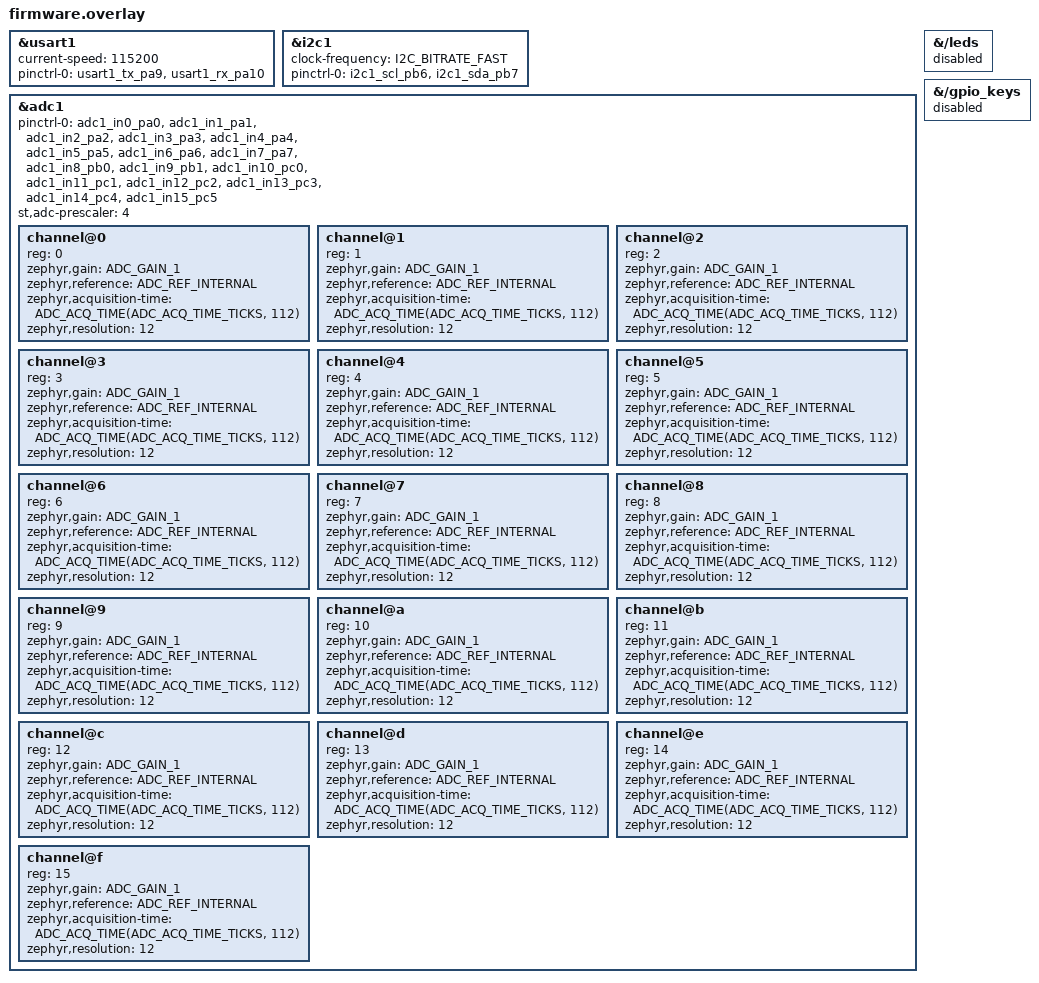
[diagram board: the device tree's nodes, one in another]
&usart1 {
    current-speed = <115200>;
    pinctrl-0 = <&usart1_tx_pa9 &usart1_rx_pa10>;
    pinctrl-names = "default";
    status = "okay";
};

&i2c1 {
    clock-frequency = <I2C_BITRATE_FAST>;
    pinctrl-0 = <&i2c1_scl_pb6 &i2c1_sda_pb7>;
    pinctrl-names = "default";
    status = "okay";
};

&adc1 {
    pinctrl-0 = <&adc1_in0_pa0
                 &adc1_in1_pa1
                 &adc1_in2_pa2
                 &adc1_in3_pa3
                 &adc1_in4_pa4
                 &adc1_in5_pa5
                 &adc1_in6_pa6
                 &adc1_in7_pa7
                 &adc1_in8_pb0
                 &adc1_in9_pb1
                 &adc1_in10_pc0
                 &adc1_in11_pc1
                 &adc1_in12_pc2
                 &adc1_in13_pc3
                 &adc1_in14_pc4
                 &adc1_in15_pc5>;
    pinctrl-names = "default";
    st,adc-prescaler = <4>;
    status = "okay";

    #address-cells = <1>;
    #size-cells = <0>;

    channel@0 {
        reg = <0>;
        zephyr,gain = "ADC_GAIN_1";
        zephyr,reference = "ADC_REF_INTERNAL";
        zephyr,acquisition-time = <ADC_ACQ_TIME(ADC_ACQ_TIME_TICKS, 112)>;
        zephyr,resolution = <12>;
    };

    channel@1 {
        reg = <1>;
        zephyr,gain = "ADC_GAIN_1";
        zephyr,reference = "ADC_REF_INTERNAL";
        zephyr,acquisition-time = <ADC_ACQ_TIME(ADC_ACQ_TIME_TICKS, 112)>;
        zephyr,resolution = <12>;
    };

    channel@2 {
        reg = <2>;
        zephyr,gain = "ADC_GAIN_1";
        zephyr,reference = "ADC_REF_INTERNAL";
        zephyr,acquisition-time = <ADC_ACQ_TIME(ADC_ACQ_TIME_TICKS, 112)>;
        zephyr,resolution = <12>;
    };

    channel@3 {
        reg = <3>;
        zephyr,gain = "ADC_GAIN_1";
        zephyr,reference = "ADC_REF_INTERNAL";
        zephyr,acquisition-time = <ADC_ACQ_TIME(ADC_ACQ_TIME_TICKS, 112)>;
        zephyr,resolution = <12>;
    };

    channel@4 {
        reg = <4>;
        zephyr,gain = "ADC_GAIN_1";
        zephyr,reference = "ADC_REF_INTERNAL";
        zephyr,acquisition-time = <ADC_ACQ_TIME(ADC_ACQ_TIME_TICKS, 112)>;
        zephyr,resolution = <12>;
    };

    channel@5 {
        reg = <5>;
        zephyr,gain = "ADC_GAIN_1";
        zephyr,reference = "ADC_REF_INTERNAL";
        zephyr,acquisition-time = <ADC_ACQ_TIME(ADC_ACQ_TIME_TICKS, 112)>;
        zephyr,resolution = <12>;
    };

    channel@6 {
        reg = <6>;
        zephyr,gain = "ADC_GAIN_1";
        zephyr,reference = "ADC_REF_INTERNAL";
        zephyr,acquisition-time = <ADC_ACQ_TIME(ADC_ACQ_TIME_TICKS, 112)>;
        zephyr,resolution = <12>;
    };

    channel@7 {
        reg = <7>;
        zephyr,gain = "ADC_GAIN_1";
        zephyr,reference = "ADC_REF_INTERNAL";
        zephyr,acquisition-time = <ADC_ACQ_TIME(ADC_ACQ_TIME_TICKS, 112)>;
        zephyr,resolution = <12>;
    };

    channel@8 {
        reg = <8>;
        zephyr,gain = "ADC_GAIN_1";
        zephyr,reference = "ADC_REF_INTERNAL";
        zephyr,acquisition-time = <ADC_ACQ_TIME(ADC_ACQ_TIME_TICKS, 112)>;
        zephyr,resolution = <12>;
    };

    channel@9 {
        reg = <9>;
        zephyr,gain = "ADC_GAIN_1";
        zephyr,reference = "ADC_REF_INTERNAL";
        zephyr,acquisition-time = <ADC_ACQ_TIME(ADC_ACQ_TIME_TICKS, 112)>;
        zephyr,resolution = <12>;
    };

    channel@a {
        reg = <10>;
        zephyr,gain = "ADC_GAIN_1";
        zephyr,reference = "ADC_REF_INTERNAL";
        zephyr,acquisition-time = <ADC_ACQ_TIME(ADC_ACQ_TIME_TICKS, 112)>;
        zephyr,resolution = <12>;
    };

    channel@b {
        reg = <11>;
        zephyr,gain = "ADC_GAIN_1";
        zephyr,reference = "ADC_REF_INTERNAL";
        zephyr,acquisition-time = <ADC_ACQ_TIME(ADC_ACQ_TIME_TICKS, 112)>;
        zephyr,resolution = <12>;
    };

    channel@c {
        reg = <12>;
        zephyr,gain = "ADC_GAIN_1";
        zephyr,reference = "ADC_REF_INTERNAL";
        zephyr,acquisition-time = <ADC_ACQ_TIME(ADC_ACQ_TIME_TICKS, 112)>;
        zephyr,resolution = <12>;
    };

    channel@d {
        reg = <13>;
        zephyr,gain = "ADC_GAIN_1";
        zephyr,reference = "ADC_REF_INTERNAL";
        zephyr,acquisition-time = <ADC_ACQ_TIME(ADC_ACQ_TIME_TICKS, 112)>;
        zephyr,resolution = <12>;
    };

    channel@e {
        reg = <14>;
        zephyr,gain = "ADC_GAIN_1";
        zephyr,reference = "ADC_REF_INTERNAL";
        zephyr,acquisition-time = <ADC_ACQ_TIME(ADC_ACQ_TIME_TICKS, 112)>;
        zephyr,resolution = <12>;
    };

    channel@f {
        reg = <15>;
        zephyr,gain = "ADC_GAIN_1";
        zephyr,reference = "ADC_REF_INTERNAL";
        zephyr,acquisition-time = <ADC_ACQ_TIME(ADC_ACQ_TIME_TICKS, 112)>;
        zephyr,resolution = <12>;
    };
};

&{/leds} {
    status = "disabled";
};

&{/gpio_keys} {
    status = "disabled";
};
